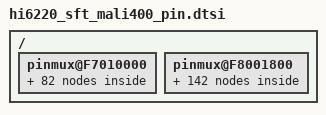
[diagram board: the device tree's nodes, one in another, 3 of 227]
/ {
    pinmux@F7010000 {
		gpio037_pmx_func: gpio037_pmx_func {
                     pinctrl-single,pins = <0x0    0x0>;
		};
		gpio037_pmx_idle: gpio037_pmx_idle {
                     pinctrl-single,pins = <0x0    0x0>;
		};

		gpio040_pmx_func: gpio040_pmx_func {
                     pinctrl-single,pins = <0x4    0x0>;
		};
		gpio040_pmx_idle: gpio040_pmx_idle {
                     pinctrl-single,pins = <0x4    0x0>;
		};

		gpio041_pmx_func: gpio041_pmx_func {
                     pinctrl-single,pins = <0x8    0x0>;
		};
		gpio041_pmx_idle: gpio041_pmx_idle {
                     pinctrl-single,pins = <0x8    0x0>;
		};

		gpio044_pmx_func: gpio044_pmx_func {
                     pinctrl-single,pins = <0xC    0x0>;
		};
		gpio044_pmx_idle: gpio044_pmx_idle {
                     pinctrl-single,pins = <0xC    0x0>;
		};

		gpio045_pmx_func: gpio045_pmx_func {
                     pinctrl-single,pins = <0x10    0x0>;
		};
		gpio045_pmx_idle: gpio045_pmx_idle {
                     pinctrl-single,pins = <0x10    0x0>;
		};

		gpio046_pmx_func: gpio046_pmx_func {
                     pinctrl-single,pins = <0x14    0x0>;
		};
		gpio046_pmx_idle: gpio046_pmx_idle {
                     pinctrl-single,pins = <0x14    0x0>;
		};

		gpio047_pmx_func: gpio047_pmx_func {
                     pinctrl-single,pins = <0x18    0x0>;
		};
		gpio047_pmx_idle: gpio047_pmx_idle {
                     pinctrl-single,pins = <0x18    0x0>;
		};

		gpio048_pmx_func: gpio048_pmx_func {
                     pinctrl-single,pins = <0x1C    0x0>;
		};
		gpio048_pmx_idle: gpio048_pmx_idle {
                     pinctrl-single,pins = <0x1C    0x0>;
		};

		gpio049_pmx_func: gpio049_pmx_func {
                     pinctrl-single,pins = <0x20    0x0>;
		};
		gpio049_pmx_idle: gpio049_pmx_idle {
                     pinctrl-single,pins = <0x20    0x0>;
		};

		gpio051_pmx_func: gpio051_pmx_func {
                     pinctrl-single,pins = <0x24    0x0>;
		};
		gpio051_pmx_idle: gpio051_pmx_idle {
                     pinctrl-single,pins = <0x24    0x0>;
		};

		gpio052_pmx_func: gpio052_pmx_func {
                     pinctrl-single,pins = <0x28    0x0>;
		};
		gpio052_pmx_idle: gpio052_pmx_idle {
                     pinctrl-single,pins = <0x28    0x0>;
		};

		gpio053_pmx_func: gpio053_pmx_func {
                     pinctrl-single,pins = <0x2C    0x0>;
		};
		gpio053_pmx_idle: gpio053_pmx_idle {
                     pinctrl-single,pins = <0x2C    0x0>;
		};

		gpio054_pmx_func: gpio054_pmx_func {
                     pinctrl-single,pins = <0x30    0x0>;
		};
		gpio054_pmx_idle: gpio054_pmx_idle {
                     pinctrl-single,pins = <0x30    0x0>;
		};

		gpio056_pmx_func: gpio056_pmx_func {
                     pinctrl-single,pins = <0x34    0x0>;
		};
		gpio056_pmx_idle: gpio056_pmx_idle {
                     pinctrl-single,pins = <0x34    0x0>;
		};

		gpio057_pmx_func: gpio057_pmx_func {
                     pinctrl-single,pins = <0x38    0x0>;
		};
		gpio057_pmx_idle: gpio057_pmx_idle {
                     pinctrl-single,pins = <0x38    0x0>;
		};

		gpio058_pmx_func: gpio058_pmx_func {
                     pinctrl-single,pins = <0x3C    0x0>;
		};
		gpio058_pmx_idle: gpio058_pmx_idle {
                     pinctrl-single,pins = <0x3C    0x0>;
		};

		gpio059_pmx_func: gpio059_pmx_func {
                     pinctrl-single,pins = <0x40    0x0>;
		};
		gpio059_pmx_idle: gpio059_pmx_idle {
                     pinctrl-single,pins = <0x40    0x0>;
		};

		gpio062_pmx_func: gpio062_pmx_func {
                     pinctrl-single,pins = <0x44    0x0>;
		};
		gpio062_pmx_idle: gpio062_pmx_idle {
                     pinctrl-single,pins = <0x44    0x0>;
		};

		gpio063_pmx_func: gpio063_pmx_func {
                     pinctrl-single,pins = <0x48    0x0>;
		};
		gpio063_pmx_idle: gpio063_pmx_idle {
                     pinctrl-single,pins = <0x48    0x0>;
		};

		gpio064_pmx_func: gpio064_pmx_func {
                     pinctrl-single,pins = <0x4C    0x0>;
		};
		gpio064_pmx_idle: gpio064_pmx_idle {
                     pinctrl-single,pins = <0x4C    0x0>;
		};

		gpio065_pmx_func: gpio065_pmx_func {
                     pinctrl-single,pins = <0x50    0x0>;
		};
		gpio065_pmx_idle: gpio065_pmx_idle {
                     pinctrl-single,pins = <0x50    0x0>;
		};

		gpio066_pmx_func: gpio066_pmx_func {
                     pinctrl-single,pins = <0x54    0x0>;
		};
		gpio066_pmx_idle: gpio066_pmx_idle {
                     pinctrl-single,pins = <0x54    0x0>;
		};

		gpio067_pmx_func: gpio067_pmx_func {
                     pinctrl-single,pins = <0x58    0x0>;
		};
		gpio067_pmx_idle: gpio067_pmx_idle {
                     pinctrl-single,pins = <0x58    0x0>;
		};

		gpio068_pmx_func: gpio068_pmx_func {
                     pinctrl-single,pins = <0x5C    0x0>;
		};
		gpio068_pmx_idle: gpio068_pmx_idle {
                     pinctrl-single,pins = <0x5C    0x0>;
		};

		gpio071_pmx_func: gpio071_pmx_func {
                     pinctrl-single,pins = <0x60    0x0>;
		};
		gpio071_pmx_idle: gpio071_pmx_idle {
                     pinctrl-single,pins = <0x60    0x0>;
		};

		gpio072_pmx_func: gpio072_pmx_func {
                     pinctrl-single,pins = <0x64    0x0>;
		};
		gpio072_pmx_idle: gpio072_pmx_idle {
                     pinctrl-single,pins = <0x64    0x0>;
		};

		gpio074_pmx_func: gpio074_pmx_func {
                     pinctrl-single,pins = <0x68    0x0>;
		};
		gpio074_pmx_idle: gpio074_pmx_idle {
                     pinctrl-single,pins = <0x68    0x0>;
		};

		gpio075_pmx_func: gpio075_pmx_func {
                     pinctrl-single,pins = <0x6C    0x0>;
		};
		gpio075_pmx_idle: gpio075_pmx_idle {
                     pinctrl-single,pins = <0x6C    0x0>;
		};

		gpio077_pmx_func: gpio077_pmx_func {
                     pinctrl-single,pins = <0x70    0x0>;
		};
		gpio077_pmx_idle: gpio077_pmx_idle {
                     pinctrl-single,pins = <0x70    0x0>;
		};

		gpio078_pmx_func: gpio078_pmx_func {
                     pinctrl-single,pins = <0x74    0x0>;
		};
		gpio078_pmx_idle: gpio078_pmx_idle {
                     pinctrl-single,pins = <0x74    0x0>;
		};

		gpio079_pmx_func: gpio079_pmx_func {
                     pinctrl-single,pins = <0x78    0x0>;
		};
		gpio079_pmx_idle: gpio079_pmx_idle {
                     pinctrl-single,pins = <0x78    0x0>;
		};

		gpio080_pmx_func: gpio080_pmx_func {
                     pinctrl-single,pins = <0x7C    0x0>;
		};
		gpio080_pmx_idle: gpio080_pmx_idle {
                     pinctrl-single,pins = <0x7C    0x0>;
		};

		gpio081_pmx_func: gpio081_pmx_func {
                     pinctrl-single,pins = <0x80    0x0>;
		};
		gpio081_pmx_idle: gpio081_pmx_idle {
                     pinctrl-single,pins = <0x80    0x0>;
		};

		gpio082_pmx_func: gpio082_pmx_func {
                     pinctrl-single,pins = <0x84    0x0>;
		};
		gpio082_pmx_idle: gpio082_pmx_idle {
                     pinctrl-single,pins = <0x84    0x0>;
		};

		gpio084_pmx_func: gpio084_pmx_func {
                     pinctrl-single,pins = <0x88    0x0>;
		};
		gpio084_pmx_idle: gpio084_pmx_idle {
                     pinctrl-single,pins = <0x88    0x0>;
		};

		gpio085_pmx_func: gpio085_pmx_func {
                     pinctrl-single,pins = <0x8C    0x0>;
		};
		gpio085_pmx_idle: gpio085_pmx_idle {
                     pinctrl-single,pins = <0x8C    0x0>;
		};

		gpio086_pmx_func: gpio086_pmx_func {
                     pinctrl-single,pins = <0x90    0x0>;
		};
		gpio086_pmx_idle: gpio086_pmx_idle {
                     pinctrl-single,pins = <0x90    0x0>;
		};

		gpio087_pmx_func: gpio087_pmx_func {
                     pinctrl-single,pins = <0x94    0x0>;
		};
		gpio087_pmx_idle: gpio087_pmx_idle {
                     pinctrl-single,pins = <0x94    0x0>;
		};

		gpio088_pmx_func: gpio088_pmx_func {
                     pinctrl-single,pins = <0x98    0x0>;
		};
		gpio088_pmx_idle: gpio088_pmx_idle {
                     pinctrl-single,pins = <0x98    0x0>;
		};

		gpio089_pmx_func: gpio089_pmx_func {
                     pinctrl-single,pins = <0x9C    0x0>;
		};
		gpio089_pmx_idle: gpio089_pmx_idle {
                     pinctrl-single,pins = <0x9C    0x0>;
		};

		gpio090_pmx_func: gpio090_pmx_func {
                     pinctrl-single,pins = <0xA0    0x0>;
		};
		gpio090_pmx_idle: gpio090_pmx_idle {
                     pinctrl-single,pins = <0xA0    0x0>;
		};

    };

    pinmux@F8001800 {
		gpio000_cfg_func: gpio000_cfg_func {
                     pinctrl-single,pins = <0x10  0>;
                     pinctrl-single,bias-pulldown = <0 2 0 2>;
                     pinctrl-single,bias-pullup = <0 1 0 1>;
                     pinctrl-single,drive-strength = <0x20 0x70>;
                     pinctrl-single,slew-rate = <0x0 0x80>;
		};
		gpio000_cfg_idle: gpio000_cfg_idle {
                     pinctrl-single,pins = <0x10  0>;
                     pinctrl-single,bias-pulldown = <0 2 0 2>;
                     pinctrl-single,bias-pullup = <0 1 0 1>;
                     pinctrl-single,drive-strength = <0x20 0x70>;
                     pinctrl-single,slew-rate = <0x0 0x80>;
		};

		gpio004_cfg_func: gpio004_cfg_func {
                     pinctrl-single,pins = <0x14  0>;
                     pinctrl-single,bias-pulldown = <0 2 0 2>;
                     pinctrl-single,bias-pullup = <0 1 0 1>;
                     pinctrl-single,drive-strength = <0x20 0x70>;
                     pinctrl-single,slew-rate = <0x0 0x80>;
		};
		gpio004_cfg_idle: gpio004_cfg_idle {
                     pinctrl-single,pins = <0x14  0>;
                     pinctrl-single,bias-pulldown = <0 2 0 2>;
                     pinctrl-single,bias-pullup = <0 1 0 1>;
                     pinctrl-single,drive-strength = <0x20 0x70>;
                     pinctrl-single,slew-rate = <0x0 0x80>;
		};

		gpio006_cfg_func: gpio006_cfg_func {
                     pinctrl-single,pins = <0x18  0>;
                     pinctrl-single,bias-pulldown = <0 2 0 2>;
                     pinctrl-single,bias-pullup = <0 1 0 1>;
                     pinctrl-single,drive-strength = <0x20 0x70>;
                     pinctrl-single,slew-rate = <0x0 0x80>;
		};
		gpio006_cfg_idle: gpio006_cfg_idle {
                     pinctrl-single,pins = <0x18  0>;
                     pinctrl-single,bias-pulldown = <0 2 0 2>;
                     pinctrl-single,bias-pullup = <0 1 0 1>;
                     pinctrl-single,drive-strength = <0x20 0x70>;
                     pinctrl-single,slew-rate = <0x0 0x80>;
		};

		gpio007_cfg_func: gpio007_cfg_func {
                     pinctrl-single,pins = <0x1C  0>;
                     pinctrl-single,bias-pulldown = <0 2 0 2>;
                     pinctrl-single,bias-pullup = <0 1 0 1>;
                     pinctrl-single,drive-strength = <0x20 0x70>;
                     pinctrl-single,slew-rate = <0x0 0x80>;
		};
		gpio007_cfg_idle: gpio007_cfg_idle {
                     pinctrl-single,pins = <0x1C  0>;
                     pinctrl-single,bias-pulldown = <0 2 0 2>;
                     pinctrl-single,bias-pullup = <0 1 0 1>;
                     pinctrl-single,drive-strength = <0x20 0x70>;
                     pinctrl-single,slew-rate = <0x0 0x80>;
		};

		gpio010_cfg_func: gpio010_cfg_func {
                     pinctrl-single,pins = <0x20  0>;
                     pinctrl-single,bias-pulldown = <0 2 0 2>;
                     pinctrl-single,bias-pullup = <0 1 0 1>;
                     pinctrl-single,drive-strength = <0x20 0x70>;
                     pinctrl-single,slew-rate = <0x0 0x80>;
		};
		gpio010_cfg_idle: gpio010_cfg_idle {
                     pinctrl-single,pins = <0x20  0>;
                     pinctrl-single,bias-pulldown = <0 2 0 2>;
                     pinctrl-single,bias-pullup = <0 1 0 1>;
                     pinctrl-single,drive-strength = <0x20 0x70>;
                     pinctrl-single,slew-rate = <0x0 0x80>;
		};

		gpio011_cfg_func: gpio011_cfg_func {
                     pinctrl-single,pins = <0x24  0>;
                     pinctrl-single,bias-pulldown = <0 2 0 2>;
                     pinctrl-single,bias-pullup = <0 1 0 1>;
                     pinctrl-single,drive-strength = <0x20 0x70>;
                     pinctrl-single,slew-rate = <0x0 0x80>;
		};
		gpio011_cfg_idle: gpio011_cfg_idle {
                     pinctrl-single,pins = <0x24  0>;
                     pinctrl-single,bias-pulldown = <0 2 0 2>;
                     pinctrl-single,bias-pullup = <0 1 0 1>;
                     pinctrl-single,drive-strength = <0x20 0x70>;
                     pinctrl-single,slew-rate = <0x0 0x80>;
		};

		gpio012_cfg_func: gpio012_cfg_func {
                     pinctrl-single,pins = <0x28  0>;
                     pinctrl-single,bias-pulldown = <0 2 0 2>;
                     pinctrl-single,bias-pullup = <0 1 0 1>;
                     pinctrl-single,drive-strength = <0x20 0x70>;
                     pinctrl-single,slew-rate = <0x0 0x80>;
		};
		gpio012_cfg_idle: gpio012_cfg_idle {
                     pinctrl-single,pins = <0x28  0>;
                     pinctrl-single,bias-pulldown = <0 2 0 2>;
                     pinctrl-single,bias-pullup = <0 1 0 1>;
                     pinctrl-single,drive-strength = <0x20 0x70>;
                     pinctrl-single,slew-rate = <0x0 0x80>;
		};

		gpio016_cfg_func: gpio016_cfg_func {
                     pinctrl-single,pins = <0x2C  0>;
                     pinctrl-single,bias-pulldown = <0 2 0 2>;
                     pinctrl-single,bias-pullup = <0 1 0 1>;
                     pinctrl-single,drive-strength = <0x20 0x70>;
                     pinctrl-single,slew-rate = <0x0 0x80>;
		};
		gpio016_cfg_idle: gpio016_cfg_idle {
                     pinctrl-single,pins = <0x2C  0>;
                     pinctrl-single,bias-pulldown = <0 2 0 2>;
                     pinctrl-single,bias-pullup = <0 1 0 1>;
                     pinctrl-single,drive-strength = <0x20 0x70>;
                     pinctrl-single,slew-rate = <0x0 0x80>;
		};

		gpio017_cfg_func: gpio017_cfg_func {
                     pinctrl-single,pins = <0x30  0>;
                     pinctrl-single,bias-pulldown = <0 2 0 2>;
                     pinctrl-single,bias-pullup = <0 1 0 1>;
                     pinctrl-single,drive-strength = <0x20 0x70>;
                     pinctrl-single,slew-rate = <0x0 0x80>;
		};
		gpio017_cfg_idle: gpio017_cfg_idle {
                     pinctrl-single,pins = <0x30  0>;
                     pinctrl-single,bias-pulldown = <0 2 0 2>;
                     pinctrl-single,bias-pullup = <0 1 0 1>;
                     pinctrl-single,drive-strength = <0x20 0x70>;
                     pinctrl-single,slew-rate = <0x0 0x80>;
		};

		gpio019_cfg_func: gpio019_cfg_func {
                     pinctrl-single,pins = <0x34  0>;
                     pinctrl-single,bias-pulldown = <0 2 0 2>;
                     pinctrl-single,bias-pullup = <0 1 0 1>;
                     pinctrl-single,drive-strength = <0x20 0x70>;
                     pinctrl-single,slew-rate = <0x0 0x80>;
		};
		gpio019_cfg_idle: gpio019_cfg_idle {
                     pinctrl-single,pins = <0x34  0>;
                     pinctrl-single,bias-pulldown = <0 2 0 2>;
                     pinctrl-single,bias-pullup = <0 1 0 1>;
                     pinctrl-single,drive-strength = <0x20 0x70>;
                     pinctrl-single,slew-rate = <0x0 0x80>;
		};

		gpio020_cfg_func: gpio020_cfg_func {
                     pinctrl-single,pins = <0x38  0>;
                     pinctrl-single,bias-pulldown = <0 2 0 2>;
                     pinctrl-single,bias-pullup = <0 1 0 1>;
                     pinctrl-single,drive-strength = <0x20 0x70>;
                     pinctrl-single,slew-rate = <0x0 0x80>;
		};
		gpio020_cfg_idle: gpio020_cfg_idle {
                     pinctrl-single,pins = <0x38  0>;
                     pinctrl-single,bias-pulldown = <0 2 0 2>;
                     pinctrl-single,bias-pullup = <0 1 0 1>;
                     pinctrl-single,drive-strength = <0x20 0x70>;
                     pinctrl-single,slew-rate = <0x0 0x80>;
		};

		gpio021_cfg_func: gpio021_cfg_func {
                     pinctrl-single,pins = <0x3C  0>;
                     pinctrl-single,bias-pulldown = <0 2 0 2>;
                     pinctrl-single,bias-pullup = <0 1 0 1>;
                     pinctrl-single,drive-strength = <0x20 0x70>;
                     pinctrl-single,slew-rate = <0x0 0x80>;
		};
		gpio021_cfg_idle: gpio021_cfg_idle {
                     pinctrl-single,pins = <0x3C  0>;
                     pinctrl-single,bias-pulldown = <0 2 0 2>;
                     pinctrl-single,bias-pullup = <0 1 0 1>;
                     pinctrl-single,drive-strength = <0x20 0x70>;
                     pinctrl-single,slew-rate = <0x0 0x80>;
		};

		gpio022_cfg_func: gpio022_cfg_func {
                     pinctrl-single,pins = <0x40  0>;
                     pinctrl-single,bias-pulldown = <0 2 0 2>;
                     pinctrl-single,bias-pullup = <0 1 0 1>;
                     pinctrl-single,drive-strength = <0x20 0x70>;
                     pinctrl-single,slew-rate = <0x0 0x80>;
		};
		gpio022_cfg_idle: gpio022_cfg_idle {
                     pinctrl-single,pins = <0x40  0>;
                     pinctrl-single,bias-pulldown = <0 2 0 2>;
                     pinctrl-single,bias-pullup = <0 1 0 1>;
                     pinctrl-single,drive-strength = <0x20 0x70>;
                     pinctrl-single,slew-rate = <0x0 0x80>;
		};

		gpio023_cfg_func: gpio023_cfg_func {
                     pinctrl-single,pins = <0x44  0>;
                     pinctrl-single,bias-pulldown = <0 2 0 2>;
                     pinctrl-single,bias-pullup = <0 1 0 1>;
                     pinctrl-single,drive-strength = <0x20 0x70>;
                     pinctrl-single,slew-rate = <0x0 0x80>;
		};
		gpio023_cfg_idle: gpio023_cfg_idle {
                     pinctrl-single,pins = <0x44  0>;
                     pinctrl-single,bias-pulldown = <0 2 0 2>;
                     pinctrl-single,bias-pullup = <0 1 0 1>;
                     pinctrl-single,drive-strength = <0x20 0x70>;
                     pinctrl-single,slew-rate = <0x0 0x80>;
		};

		gpio024_cfg_func: gpio024_cfg_func {
                     pinctrl-single,pins = <0x48  0>;
                     pinctrl-single,bias-pulldown = <0 2 0 2>;
                     pinctrl-single,bias-pullup = <0 1 0 1>;
                     pinctrl-single,drive-strength = <0x20 0x70>;
                     pinctrl-single,slew-rate = <0x0 0x80>;
		};
		gpio024_cfg_idle: gpio024_cfg_idle {
                     pinctrl-single,pins = <0x48  0>;
                     pinctrl-single,bias-pulldown = <0 2 0 2>;
                     pinctrl-single,bias-pullup = <0 1 0 1>;
                     pinctrl-single,drive-strength = <0x20 0x70>;
                     pinctrl-single,slew-rate = <0x0 0x80>;
		};

		gpio025_cfg_func: gpio025_cfg_func {
                     pinctrl-single,pins = <0x4C  0>;
                     pinctrl-single,bias-pulldown = <0 2 0 2>;
                     pinctrl-single,bias-pullup = <0 1 0 1>;
                     pinctrl-single,drive-strength = <0x20 0x70>;
                     pinctrl-single,slew-rate = <0x0 0x80>;
		};
		gpio025_cfg_idle: gpio025_cfg_idle {
                     pinctrl-single,pins = <0x4C  0>;
                     pinctrl-single,bias-pulldown = <0 2 0 2>;
                     pinctrl-single,bias-pullup = <0 1 0 1>;
                     pinctrl-single,drive-strength = <0x20 0x70>;
                     pinctrl-single,slew-rate = <0x0 0x80>;
		};

		gpio026_cfg_func: gpio026_cfg_func {
                     pinctrl-single,pins = <0x50  0>;
                     pinctrl-single,bias-pulldown = <0 2 0 2>;
                     pinctrl-single,bias-pullup = <0 1 0 1>;
                     pinctrl-single,drive-strength = <0x20 0x70>;
                     pinctrl-single,slew-rate = <0x0 0x80>;
		};
		gpio026_cfg_idle: gpio026_cfg_idle {
                     pinctrl-single,pins = <0x50  0>;
                     pinctrl-single,bias-pulldown = <0 2 0 2>;
                     pinctrl-single,bias-pullup = <0 1 0 1>;
                     pinctrl-single,drive-strength = <0x20 0x70>;
                     pinctrl-single,slew-rate = <0x0 0x80>;
		};

		gpio027_cfg_func: gpio027_cfg_func {
                     pinctrl-single,pins = <0x54  0>;
                     pinctrl-single,bias-pulldown = <0 2 0 2>;
                     pinctrl-single,bias-pullup = <0 1 0 1>;
                     pinctrl-single,drive-strength = <0x20 0x70>;
                     pinctrl-single,slew-rate = <0x0 0x80>;
		};
		gpio027_cfg_idle: gpio027_cfg_idle {
                     pinctrl-single,pins = <0x54  0>;
                     pinctrl-single,bias-pulldown = <0 2 0 2>;
                     pinctrl-single,bias-pullup = <0 1 0 1>;
                     pinctrl-single,drive-strength = <0x20 0x70>;
                     pinctrl-single,slew-rate = <0x0 0x80>;
		};

		gpio028_cfg_func: gpio028_cfg_func {
                     pinctrl-single,pins = <0x58  0>;
                     pinctrl-single,bias-pulldown = <0 2 0 2>;
                     pinctrl-single,bias-pullup = <0 1 0 1>;
                     pinctrl-single,drive-strength = <0x20 0x70>;
                     pinctrl-single,slew-rate = <0x0 0x80>;
		};
		gpio028_cfg_idle: gpio028_cfg_idle {
                     pinctrl-single,pins = <0x58  0>;
                     pinctrl-single,bias-pulldown = <0 2 0 2>;
                     pinctrl-single,bias-pullup = <0 1 0 1>;
                     pinctrl-single,drive-strength = <0x20 0x70>;
                     pinctrl-single,slew-rate = <0x0 0x80>;
		};

		gpio029_cfg_func: gpio029_cfg_func {
                     pinctrl-single,pins = <0x5C  0>;
                     pinctrl-single,bias-pulldown = <0 2 0 2>;
                     pinctrl-single,bias-pullup = <0 1 0 1>;
                     pinctrl-single,drive-strength = <0x20 0x70>;
                     pinctrl-single,slew-rate = <0x0 0x80>;
		};
		gpio029_cfg_idle: gpio029_cfg_idle {
                     pinctrl-single,pins = <0x5C  0>;
                     pinctrl-single,bias-pulldown = <0 2 0 2>;
                     pinctrl-single,bias-pullup = <0 1 0 1>;
                     pinctrl-single,drive-strength = <0x20 0x70>;
                     pinctrl-single,slew-rate = <0x0 0x80>;
		};

		gpio030_cfg_func: gpio030_cfg_func {
                     pinctrl-single,pins = <0x60  0>;
                     pinctrl-single,bias-pulldown = <0 2 0 2>;
                     pinctrl-single,bias-pullup = <0 1 0 1>;
                     pinctrl-single,drive-strength = <0x20 0x70>;
                     pinctrl-single,slew-rate = <0x0 0x80>;
		};
		gpio030_cfg_idle: gpio030_cfg_idle {
                     pinctrl-single,pins = <0x60  0>;
                     pinctrl-single,bias-pulldown = <0 2 0 2>;
                     pinctrl-single,bias-pullup = <0 1 0 1>;
                     pinctrl-single,drive-strength = <0x20 0x70>;
                     pinctrl-single,slew-rate = <0x0 0x80>;
		};

		gpio031_cfg_func: gpio031_cfg_func {
                     pinctrl-single,pins = <0x64  0>;
                     pinctrl-single,bias-pulldown = <0 2 0 2>;
                     pinctrl-single,bias-pullup = <0 1 0 1>;
                     pinctrl-single,drive-strength = <0x20 0x70>;
                     pinctrl-single,slew-rate = <0x0 0x80>;
		};
		gpio031_cfg_idle: gpio031_cfg_idle {
                     pinctrl-single,pins = <0x64  0>;
                     pinctrl-single,bias-pulldown = <0 2 0 2>;
                     pinctrl-single,bias-pullup = <0 1 0 1>;
                     pinctrl-single,drive-strength = <0x20 0x70>;
                     pinctrl-single,slew-rate = <0x0 0x80>;
		};

		gpio032_cfg_func: gpio032_cfg_func {
                     pinctrl-single,pins = <0x68  0>;
                     pinctrl-single,bias-pulldown = <0 2 0 2>;
                     pinctrl-single,bias-pullup = <0 1 0 1>;
                     pinctrl-single,drive-strength = <0x20 0x70>;
                     pinctrl-single,slew-rate = <0x0 0x80>;
		};
		gpio032_cfg_idle: gpio032_cfg_idle {
                     pinctrl-single,pins = <0x68  0>;
                     pinctrl-single,bias-pulldown = <0 2 0 2>;
                     pinctrl-single,bias-pullup = <0 1 0 1>;
                     pinctrl-single,drive-strength = <0x20 0x70>;
                     pinctrl-single,slew-rate = <0x0 0x80>;
		};

		gpio033_cfg_func: gpio033_cfg_func {
                     pinctrl-single,pins = <0x6C  0>;
                     pinctrl-single,bias-pulldown = <0 2 0 2>;
                     pinctrl-single,bias-pullup = <0 1 0 1>;
                     pinctrl-single,drive-strength = <0x20 0x70>;
                     pinctrl-single,slew-rate = <0x0 0x80>;
		};
		gpio033_cfg_idle: gpio033_cfg_idle {
                     pinctrl-single,pins = <0x6C  0>;
                     pinctrl-single,bias-pulldown = <0 2 0 2>;
                     pinctrl-single,bias-pullup = <0 1 0 1>;
                     pinctrl-single,drive-strength = <0x20 0x70>;
                     pinctrl-single,slew-rate = <0x0 0x80>;
		};

		gpio034_cfg_func: gpio034_cfg_func {
                     pinctrl-single,pins = <0x70  0>;
                     pinctrl-single,bias-pulldown = <0 2 0 2>;
                     pinctrl-single,bias-pullup = <0 1 0 1>;
                     pinctrl-single,drive-strength = <0x20 0x70>;
                     pinctrl-single,slew-rate = <0x0 0x80>;
		};
		gpio034_cfg_idle: gpio034_cfg_idle {
                     pinctrl-single,pins = <0x70  0>;
                     pinctrl-single,bias-pulldown = <0 2 0 2>;
                     pinctrl-single,bias-pullup = <0 1 0 1>;
                     pinctrl-single,drive-strength = <0x20 0x70>;
                     pinctrl-single,slew-rate = <0x0 0x80>;
		};

		gpio035_cfg_func: gpio035_cfg_func {
                     pinctrl-single,pins = <0x74  0>;
                     pinctrl-single,bias-pulldown = <0 2 0 2>;
                     pinctrl-single,bias-pullup = <0 1 0 1>;
                     pinctrl-single,drive-strength = <0x20 0x70>;
                     pinctrl-single,slew-rate = <0x0 0x80>;
		};
		gpio035_cfg_idle: gpio035_cfg_idle {
                     pinctrl-single,pins = <0x74  0>;
                     pinctrl-single,bias-pulldown = <0 2 0 2>;
                     pinctrl-single,bias-pullup = <0 1 0 1>;
                     pinctrl-single,drive-strength = <0x20 0x70>;
                     pinctrl-single,slew-rate = <0x0 0x80>;
		};

		gpio036_cfg_func: gpio036_cfg_func {
                     pinctrl-single,pins = <0xA8  0>;
                     pinctrl-single,bias-pulldown = <0 2 0 2>;
                     pinctrl-single,bias-pullup = <0 1 0 1>;
                     pinctrl-single,drive-strength = <0x20 0x70>;
                     pinctrl-single,slew-rate = <0x0 0x80>;
		};
		gpio036_cfg_idle: gpio036_cfg_idle {
                     pinctrl-single,pins = <0xA8  0>;
                     pinctrl-single,bias-pulldown = <0 2 0 2>;
                     pinctrl-single,bias-pullup = <0 1 0 1>;
                     pinctrl-single,drive-strength = <0x20 0x70>;
                     pinctrl-single,slew-rate = <0x0 0x80>;
		};

		gpio037_cfg_func: gpio037_cfg_func {
                     pinctrl-single,pins = <0x0  0>;
                     pinctrl-single,bias-pulldown = <0 2 0 2>;
                     pinctrl-single,bias-pullup = <0 1 0 1>;
                     pinctrl-single,drive-strength = <0x20 0x70>;
                     pinctrl-single,slew-rate = <0x0 0x80>;
		};
		gpio037_cfg_idle: gpio037_cfg_idle {
                     pinctrl-single,pins = <0x0  0>;
                     pinctrl-single,bias-pulldown = <0 2 0 2>;
                     pinctrl-single,bias-pullup = <0 1 0 1>;
                     pinctrl-single,drive-strength = <0x20 0x70>;
                     pinctrl-single,slew-rate = <0x0 0x80>;
		};

		gpio038_cfg_func: gpio038_cfg_func {
                     pinctrl-single,pins = <0xAC  0>;
                     pinctrl-single,bias-pulldown = <0 2 0 2>;
                     pinctrl-single,bias-pullup = <0 1 0 1>;
                     pinctrl-single,drive-strength = <0x20 0x70>;
                     pinctrl-single,slew-rate = <0x0 0x80>;
		};
		gpio038_cfg_idle: gpio038_cfg_idle {
                     pinctrl-single,pins = <0xAC  0>;
                     pinctrl-single,bias-pulldown = <0 2 0 2>;
                     pinctrl-single,bias-pullup = <0 1 0 1>;
                     pinctrl-single,drive-strength = <0x20 0x70>;
                     pinctrl-single,slew-rate = <0x0 0x80>;
		};

		gpio039_cfg_func: gpio039_cfg_func {
                     pinctrl-single,pins = <0xB0  0>;
                     pinctrl-single,bias-pulldown = <0 2 0 2>;
                     pinctrl-single,bias-pullup = <0 1 0 1>;
                     pinctrl-single,drive-strength = <0x20 0x70>;
                     pinctrl-single,slew-rate = <0x0 0x80>;
		};
		gpio039_cfg_idle: gpio039_cfg_idle {
                     pinctrl-single,pins = <0xB0  0>;
                     pinctrl-single,bias-pulldown = <0 2 0 2>;
                     pinctrl-single,bias-pullup = <0 1 0 1>;
                     pinctrl-single,drive-strength = <0x20 0x70>;
                     pinctrl-single,slew-rate = <0x0 0x80>;
		};

		gpio040_cfg_func: gpio040_cfg_func {
                     pinctrl-single,pins = <0x4  0>;
                     pinctrl-single,bias-pulldown = <0 2 0 2>;
                     pinctrl-single,bias-pullup = <0 1 0 1>;
                     pinctrl-single,drive-strength = <0x20 0x70>;
                     pinctrl-single,slew-rate = <0x0 0x80>;
		};
		gpio040_cfg_idle: gpio040_cfg_idle {
                     pinctrl-single,pins = <0x4  0>;
                     pinctrl-single,bias-pulldown = <0 2 0 2>;
                     pinctrl-single,bias-pullup = <0 1 0 1>;
                     pinctrl-single,drive-strength = <0x20 0x70>;
                     pinctrl-single,slew-rate = <0x0 0x80>;
		};

		gpio041_cfg_func: gpio041_cfg_func {
                     pinctrl-single,pins = <0x8  0>;
                     pinctrl-single,bias-pulldown = <0 2 0 2>;
                     pinctrl-single,bias-pullup = <0 1 0 1>;
                     pinctrl-single,drive-strength = <0x20 0x70>;
                     pinctrl-single,slew-rate = <0x0 0x80>;
		};
		gpio041_cfg_idle: gpio041_cfg_idle {
                     pinctrl-single,pins = <0x8  0>;
                     pinctrl-single,bias-pulldown = <0 2 0 2>;
                     pinctrl-single,bias-pullup = <0 1 0 1>;
                     pinctrl-single,drive-strength = <0x20 0x70>;
                     pinctrl-single,slew-rate = <0x0 0x80>;
		};

		gpio044_cfg_func: gpio044_cfg_func {
                     pinctrl-single,pins = <0xC  0>;
                     pinctrl-single,bias-pulldown = <0 2 0 2>;
                     pinctrl-single,bias-pullup = <0 1 0 1>;
                     pinctrl-single,drive-strength = <0x10 0x70>;
                     pinctrl-single,slew-rate = <0x0 0x80>;
		};
		gpio044_cfg_idle: gpio044_cfg_idle {
                     pinctrl-single,pins = <0xC  0>;
                     pinctrl-single,bias-pulldown = <0 2 0 2>;
                     pinctrl-single,bias-pullup = <0 1 0 1>;
                     pinctrl-single,drive-strength = <0x10 0x70>;
                     pinctrl-single,slew-rate = <0x0 0x80>;
		};

		gpio045_cfg_func: gpio045_cfg_func {
                     pinctrl-single,pins = <0x10  0>;
                     pinctrl-single,bias-pulldown = <0 2 0 2>;
                     pinctrl-single,bias-pullup = <0 1 0 1>;
                     pinctrl-single,drive-strength = <0x10 0x70>;
                     pinctrl-single,slew-rate = <0x0 0x80>;
		};
		gpio045_cfg_idle: gpio045_cfg_idle {
                     pinctrl-single,pins = <0x10  0>;
                     pinctrl-single,bias-pulldown = <0 2 0 2>;
                     pinctrl-single,bias-pullup = <0 1 0 1>;
                     pinctrl-single,drive-strength = <0x10 0x70>;
                     pinctrl-single,slew-rate = <0x0 0x80>;
		};

		gpio046_cfg_func: gpio046_cfg_func {
                     pinctrl-single,pins = <0x14  0>;
                     pinctrl-single,bias-pulldown = <0 2 0 2>;
                     pinctrl-single,bias-pullup = <0 1 0 1>;
                     pinctrl-single,drive-strength = <0x10 0x70>;
                     pinctrl-single,slew-rate = <0x0 0x80>;
		};
		gpio046_cfg_idle: gpio046_cfg_idle {
                     pinctrl-single,pins = <0x14  0>;
                     pinctrl-single,bias-pulldown = <0 2 0 2>;
                     pinctrl-single,bias-pullup = <0 1 0 1>;
                     pinctrl-single,drive-strength = <0x10 0x70>;
                     pinctrl-single,slew-rate = <0x0 0x80>;
		};

		gpio047_cfg_func: gpio047_cfg_func {
                     pinctrl-single,pins = <0x18  0>;
                     pinctrl-single,bias-pulldown = <0 2 0 2>;
                     pinctrl-single,bias-pullup = <0 1 0 1>;
                     pinctrl-single,drive-strength = <0x10 0x70>;
                     pinctrl-single,slew-rate = <0x0 0x80>;
		};
		gpio047_cfg_idle: gpio047_cfg_idle {
                     pinctrl-single,pins = <0x18  0>;
                     pinctrl-single,bias-pulldown = <0 2 0 2>;
                     pinctrl-single,bias-pullup = <0 1 0 1>;
                     pinctrl-single,drive-strength = <0x10 0x70>;
                     pinctrl-single,slew-rate = <0x0 0x80>;
		};

		gpio048_cfg_func: gpio048_cfg_func {
                     pinctrl-single,pins = <0x1C  0>;
                     pinctrl-single,bias-pulldown = <0 2 0 2>;
                     pinctrl-single,bias-pullup = <0 1 0 1>;
                     pinctrl-single,drive-strength = <0x10 0x70>;
                     pinctrl-single,slew-rate = <0x0 0x80>;
		};
		gpio048_cfg_idle: gpio048_cfg_idle {
                     pinctrl-single,pins = <0x1C  0>;
                     pinctrl-single,bias-pulldown = <0 2 0 2>;
                     pinctrl-single,bias-pullup = <0 1 0 1>;
                     pinctrl-single,drive-strength = <0x10 0x70>;
                     pinctrl-single,slew-rate = <0x0 0x80>;
		};

		gpio049_cfg_func: gpio049_cfg_func {
                     pinctrl-single,pins = <0x20  0>;
                     pinctrl-single,bias-pulldown = <0 2 0 2>;
                     pinctrl-single,bias-pullup = <0 1 0 1>;
                     pinctrl-single,drive-strength = <0x10 0x70>;
                     pinctrl-single,slew-rate = <0x0 0x80>;
		};
		gpio049_cfg_idle: gpio049_cfg_idle {
                     pinctrl-single,pins = <0x20  0>;
                     pinctrl-single,bias-pulldown = <0 2 0 2>;
                     pinctrl-single,bias-pullup = <0 1 0 1>;
                     pinctrl-single,drive-strength = <0x10 0x70>;
                     pinctrl-single,slew-rate = <0x0 0x80>;
		};

		gpio050_cfg_func: gpio050_cfg_func {
                     pinctrl-single,pins = <0x24  0>;
                     pinctrl-single,bias-pulldown = <0 2 0 2>;
                     pinctrl-single,bias-pullup = <0 1 0 1>;
                     pinctrl-single,drive-strength = <0x10 0x70>;
                     pinctrl-single,slew-rate = <0x0 0x80>;
		};
		gpio050_cfg_idle: gpio050_cfg_idle {
                     pinctrl-single,pins = <0x24  0>;
                     pinctrl-single,bias-pulldown = <0 2 0 2>;
                     pinctrl-single,bias-pullup = <0 1 0 1>;
                     pinctrl-single,drive-strength = <0x10 0x70>;
                     pinctrl-single,slew-rate = <0x0 0x80>;
		};

		gpio051_cfg_func: gpio051_cfg_func {
                     pinctrl-single,pins = <0x28  0>;
                     pinctrl-single,bias-pulldown = <0 2 0 2>;
                     pinctrl-single,bias-pullup = <0 1 0 1>;
                     pinctrl-single,drive-strength = <0x20 0x70>;
		};
		gpio051_cfg_idle: gpio051_cfg_idle {
                     pinctrl-single,pins = <0x28  0>;
                     pinctrl-single,bias-pulldown = <0 2 0 2>;
                     pinctrl-single,bias-pullup = <0 1 0 1>;
                     pinctrl-single,drive-strength = <0x20 0x70>;
		};

		gpio052_cfg_func: gpio052_cfg_func {
                     pinctrl-single,pins = <0x2C  0>;
                     pinctrl-single,bias-pulldown = <0 2 0 2>;
                     pinctrl-single,bias-pullup = <0 1 0 1>;
                     pinctrl-single,drive-strength = <0x20 0x70>;
                     pinctrl-single,slew-rate = <0x0 0x80>;
		};
		gpio052_cfg_idle: gpio052_cfg_idle {
                     pinctrl-single,pins = <0x2C  0>;
                     pinctrl-single,bias-pulldown = <0 2 0 2>;
                     pinctrl-single,bias-pullup = <0 1 0 1>;
                     pinctrl-single,drive-strength = <0x20 0x70>;
                     pinctrl-single,slew-rate = <0x0 0x80>;
		};

		gpio053_cfg_func: gpio053_cfg_func {
                     pinctrl-single,pins = <0x30  0>;
                     pinctrl-single,bias-pulldown = <0 2 0 2>;
                     pinctrl-single,bias-pullup = <0 1 0 1>;
                     pinctrl-single,drive-strength = <0x20 0x70>;
                     pinctrl-single,slew-rate = <0x0 0x80>;
		};
		gpio053_cfg_idle: gpio053_cfg_idle {
                     pinctrl-single,pins = <0x30  0>;
                     pinctrl-single,bias-pulldown = <0 2 0 2>;
                     pinctrl-single,bias-pullup = <0 1 0 1>;
                     pinctrl-single,drive-strength = <0x20 0x70>;
                     pinctrl-single,slew-rate = <0x0 0x80>;
		};

		gpio054_cfg_func: gpio054_cfg_func {
                     pinctrl-single,pins = <0x34  0>;
                     pinctrl-single,bias-pulldown = <0 2 0 2>;
                     pinctrl-single,bias-pullup = <0 1 0 1>;
                     pinctrl-single,drive-strength = <0x20 0x70>;
                     pinctrl-single,slew-rate = <0x0 0x80>;
		};
		gpio054_cfg_idle: gpio054_cfg_idle {
                     pinctrl-single,pins = <0x34  0>;
                     pinctrl-single,bias-pulldown = <0 2 0 2>;
                     pinctrl-single,bias-pullup = <0 1 0 1>;
                     pinctrl-single,drive-strength = <0x20 0x70>;
                     pinctrl-single,slew-rate = <0x0 0x80>;
		};

		gpio056_cfg_func: gpio056_cfg_func {
                     pinctrl-single,pins = <0x38  0>;
                     pinctrl-single,bias-pulldown = <0 2 0 2>;
                     pinctrl-single,bias-pullup = <0 1 0 1>;
                     pinctrl-single,drive-strength = <0x20 0x70>;
                     pinctrl-single,slew-rate = <0x0 0x80>;
		};
		gpio056_cfg_idle: gpio056_cfg_idle {
                     pinctrl-single,pins = <0x38  0>;
                     pinctrl-single,bias-pulldown = <0 2 0 2>;
                     pinctrl-single,bias-pullup = <0 1 0 1>;
                     pinctrl-single,drive-strength = <0x20 0x70>;
                     pinctrl-single,slew-rate = <0x0 0x80>;
		};

		gpio057_cfg_func: gpio057_cfg_func {
                     pinctrl-single,pins = <0x3C  0>;
                     pinctrl-single,bias-pulldown = <0 2 0 2>;
                     pinctrl-single,bias-pullup = <0 1 0 1>;
                     pinctrl-single,drive-strength = <0x20 0x70>;
                     pinctrl-single,slew-rate = <0x0 0x80>;
		};
		gpio057_cfg_idle: gpio057_cfg_idle {
                     pinctrl-single,pins = <0x3C  0>;
                     pinctrl-single,bias-pulldown = <0 2 0 2>;
                     pinctrl-single,bias-pullup = <0 1 0 1>;
                     pinctrl-single,drive-strength = <0x20 0x70>;
                     pinctrl-single,slew-rate = <0x0 0x80>;
		};

		gpio058_cfg_func: gpio058_cfg_func {
                     pinctrl-single,pins = <0x40  0>;
                     pinctrl-single,bias-pulldown = <0 2 0 2>;
                     pinctrl-single,bias-pullup = <0 1 0 1>;
                     pinctrl-single,drive-strength = <0x20 0x70>;
                     pinctrl-single,slew-rate = <0x0 0x80>;
		};
		gpio058_cfg_idle: gpio058_cfg_idle {
                     pinctrl-single,pins = <0x40  0>;
                     pinctrl-single,bias-pulldown = <0 2 0 2>;
                     pinctrl-single,bias-pullup = <0 1 0 1>;
                     pinctrl-single,drive-strength = <0x20 0x70>;
                     pinctrl-single,slew-rate = <0x0 0x80>;
		};

		gpio059_cfg_func: gpio059_cfg_func {
                     pinctrl-single,pins = <0x44  0>;
                     pinctrl-single,bias-pulldown = <0 2 0 2>;
                     pinctrl-single,bias-pullup = <0 1 0 1>;
                     pinctrl-single,drive-strength = <0x20 0x70>;
                     pinctrl-single,slew-rate = <0x0 0x80>;
		};
		gpio059_cfg_idle: gpio059_cfg_idle {
                     pinctrl-single,pins = <0x44  0>;
                     pinctrl-single,bias-pulldown = <0 2 0 2>;
                     pinctrl-single,bias-pullup = <0 1 0 1>;
                     pinctrl-single,drive-strength = <0x20 0x70>;
                     pinctrl-single,slew-rate = <0x0 0x80>;
		};

		gpio062_cfg_func: gpio062_cfg_func {
                     pinctrl-single,pins = <0x48  0>;
                     pinctrl-single,bias-pulldown = <0 2 0 2>;
                     pinctrl-single,bias-pullup = <0 1 0 1>;
                     pinctrl-single,drive-strength = <0x20 0x70>;
                     pinctrl-single,slew-rate = <0x0 0x80>;
		};
		gpio062_cfg_idle: gpio062_cfg_idle {
                     pinctrl-single,pins = <0x48  0>;
                     pinctrl-single,bias-pulldown = <0 2 0 2>;
                     pinctrl-single,bias-pullup = <0 1 0 1>;
                     pinctrl-single,drive-strength = <0x20 0x70>;
                     pinctrl-single,slew-rate = <0x0 0x80>;
		};

		gpio063_cfg_func: gpio063_cfg_func {
                     pinctrl-single,pins = <0x4C  0>;
                     pinctrl-single,bias-pulldown = <0 2 0 2>;
                     pinctrl-single,bias-pullup = <0 1 0 1>;
                     pinctrl-single,drive-strength = <0x20 0x70>;
                     pinctrl-single,slew-rate = <0x0 0x80>;
		};
		gpio063_cfg_idle: gpio063_cfg_idle {
                     pinctrl-single,pins = <0x4C  0>;
                     pinctrl-single,bias-pulldown = <0 2 0 2>;
                     pinctrl-single,bias-pullup = <0 1 0 1>;
                     pinctrl-single,drive-strength = <0x20 0x70>;
                     pinctrl-single,slew-rate = <0x0 0x80>;
		};

		gpio064_cfg_func: gpio064_cfg_func {
                     pinctrl-single,pins = <0x50  0>;
                     pinctrl-single,bias-pulldown = <0 2 0 2>;
                     pinctrl-single,bias-pullup = <0 1 0 1>;
                     pinctrl-single,drive-strength = <0x20 0x70>;
                     pinctrl-single,slew-rate = <0x0 0x80>;
		};
		gpio064_cfg_idle: gpio064_cfg_idle {
                     pinctrl-single,pins = <0x50  0>;
                     pinctrl-single,bias-pulldown = <0 2 0 2>;
                     pinctrl-single,bias-pullup = <0 1 0 1>;
                     pinctrl-single,drive-strength = <0x20 0x70>;
                     pinctrl-single,slew-rate = <0x0 0x80>;
		};

		gpio065_cfg_func: gpio065_cfg_func {
                     pinctrl-single,pins = <0x54  0>;
                     pinctrl-single,bias-pulldown = <0 2 0 2>;
                     pinctrl-single,bias-pullup = <0 1 0 1>;
                     pinctrl-single,drive-strength = <0x20 0x70>;
                     pinctrl-single,slew-rate = <0x0 0x80>;
		};
		gpio065_cfg_idle: gpio065_cfg_idle {
                     pinctrl-single,pins = <0x54  0>;
                     pinctrl-single,bias-pulldown = <0 2 0 2>;
                     pinctrl-single,bias-pullup = <0 1 0 1>;
                     pinctrl-single,drive-strength = <0x20 0x70>;
                     pinctrl-single,slew-rate = <0x0 0x80>;
		};

		gpio066_cfg_func: gpio066_cfg_func {
                     pinctrl-single,pins = <0x58  0>;
                     pinctrl-single,bias-pulldown = <0 2 0 2>;
                     pinctrl-single,bias-pullup = <0 1 0 1>;
                     pinctrl-single,drive-strength = <0x20 0x70>;
                     pinctrl-single,slew-rate = <0x0 0x80>;
		};
		gpio066_cfg_idle: gpio066_cfg_idle {
                     pinctrl-single,pins = <0x58  0>;
                     pinctrl-single,bias-pulldown = <0 2 0 2>;
                     pinctrl-single,bias-pullup = <0 1 0 1>;
                     pinctrl-single,drive-strength = <0x20 0x70>;
                     pinctrl-single,slew-rate = <0x0 0x80>;
		};

		gpio067_cfg_func: gpio067_cfg_func {
                     pinctrl-single,pins = <0x5C  0>;
                     pinctrl-single,bias-pulldown = <0 2 0 2>;
                     pinctrl-single,bias-pullup = <0 1 0 1>;
                     pinctrl-single,drive-strength = <0x20 0x70>;
                     pinctrl-single,slew-rate = <0x0 0x80>;
		};
		gpio067_cfg_idle: gpio067_cfg_idle {
                     pinctrl-single,pins = <0x5C  0>;
                     pinctrl-single,bias-pulldown = <0 2 0 2>;
                     pinctrl-single,bias-pullup = <0 1 0 1>;
                     pinctrl-single,drive-strength = <0x20 0x70>;
                     pinctrl-single,slew-rate = <0x0 0x80>;
		};

		gpio068_cfg_func: gpio068_cfg_func {
                     pinctrl-single,pins = <0x60  0>;
                     pinctrl-single,bias-pulldown = <0 2 0 2>;
                     pinctrl-single,bias-pullup = <0 1 0 1>;
                     pinctrl-single,drive-strength = <0x20 0x70>;
                     pinctrl-single,slew-rate = <0x0 0x80>;
		};
		gpio068_cfg_idle: gpio068_cfg_idle {
                     pinctrl-single,pins = <0x60  0>;
                     pinctrl-single,bias-pulldown = <0 2 0 2>;
                     pinctrl-single,bias-pullup = <0 1 0 1>;
                     pinctrl-single,drive-strength = <0x20 0x70>;
                     pinctrl-single,slew-rate = <0x0 0x80>;
		};

		gpio071_cfg_func: gpio071_cfg_func {
                     pinctrl-single,pins = <0x64  0>;
                     pinctrl-single,bias-pulldown = <0 2 0 2>;
                     pinctrl-single,bias-pullup = <0 1 0 1>;
                     pinctrl-single,drive-strength = <0x20 0x70>;
                     pinctrl-single,slew-rate = <0x0 0x80>;
		};
		gpio071_cfg_idle: gpio071_cfg_idle {
                     pinctrl-single,pins = <0x64  0>;
                     pinctrl-single,bias-pulldown = <0 2 0 2>;
                     pinctrl-single,bias-pullup = <0 1 0 1>;
                     pinctrl-single,drive-strength = <0x20 0x70>;
                     pinctrl-single,slew-rate = <0x0 0x80>;
		};

		gpio072_cfg_func: gpio072_cfg_func {
                     pinctrl-single,pins = <0x68  0>;
                     pinctrl-single,bias-pulldown = <0 2 0 2>;
                     pinctrl-single,bias-pullup = <0 1 0 1>;
                     pinctrl-single,drive-strength = <0x20 0x70>;
                     pinctrl-single,slew-rate = <0x0 0x80>;
		};
		gpio072_cfg_idle: gpio072_cfg_idle {
                     pinctrl-single,pins = <0x68  0>;
                     pinctrl-single,bias-pulldown = <0 2 0 2>;
                     pinctrl-single,bias-pullup = <0 1 0 1>;
                     pinctrl-single,drive-strength = <0x20 0x70>;
                     pinctrl-single,slew-rate = <0x0 0x80>;
		};

		gpio074_cfg_func: gpio074_cfg_func {
                     pinctrl-single,pins = <0x6C  0>;
                     pinctrl-single,bias-pulldown = <0 2 0 2>;
                     pinctrl-single,bias-pullup = <0 1 0 1>;
                     pinctrl-single,drive-strength = <0x20 0x70>;
                     pinctrl-single,slew-rate = <0x0 0x80>;
		};
		gpio074_cfg_idle: gpio074_cfg_idle {
                     pinctrl-single,pins = <0x6C  0>;
                     pinctrl-single,bias-pulldown = <0 2 0 2>;
                     pinctrl-single,bias-pullup = <0 1 0 1>;
                     pinctrl-single,drive-strength = <0x20 0x70>;
                     pinctrl-single,slew-rate = <0x0 0x80>;
		};

		gpio075_cfg_func: gpio075_cfg_func {
                     pinctrl-single,pins = <0x70  0>;
                     pinctrl-single,bias-pulldown = <0 2 0 2>;
                     pinctrl-single,bias-pullup = <0 1 0 1>;
                     pinctrl-single,drive-strength = <0x20 0x70>;
                     pinctrl-single,slew-rate = <0x0 0x80>;
		};
		gpio075_cfg_idle: gpio075_cfg_idle {
                     pinctrl-single,pins = <0x70  0>;
                     pinctrl-single,bias-pulldown = <0 2 0 2>;
                     pinctrl-single,bias-pullup = <0 1 0 1>;
                     pinctrl-single,drive-strength = <0x20 0x70>;
                     pinctrl-single,slew-rate = <0x0 0x80>;
		};

		gpio077_cfg_func: gpio077_cfg_func {
                     pinctrl-single,pins = <0x74  0>;
                     pinctrl-single,bias-pulldown = <0 2 0 2>;
                     pinctrl-single,bias-pullup = <0 1 0 1>;
                     pinctrl-single,drive-strength = <0x20 0x70>;
                     pinctrl-single,slew-rate = <0x0 0x80>;
		};
		gpio077_cfg_idle: gpio077_cfg_idle {
                     pinctrl-single,pins = <0x74  0>;
                     pinctrl-single,bias-pulldown = <0 2 0 2>;
                     pinctrl-single,bias-pullup = <0 1 0 1>;
                     pinctrl-single,drive-strength = <0x20 0x70>;
                     pinctrl-single,slew-rate = <0x0 0x80>;
		};

		gpio078_cfg_func: gpio078_cfg_func {
                     pinctrl-single,pins = <0x78  0>;
                     pinctrl-single,bias-pulldown = <0 2 0 2>;
                     pinctrl-single,bias-pullup = <0 1 0 1>;
                     pinctrl-single,drive-strength = <0x20 0x70>;
                     pinctrl-single,slew-rate = <0x0 0x80>;
		};
		gpio078_cfg_idle: gpio078_cfg_idle {
                     pinctrl-single,pins = <0x78  0>;
                     pinctrl-single,bias-pulldown = <0 2 0 2>;
                     pinctrl-single,bias-pullup = <0 1 0 1>;
                     pinctrl-single,drive-strength = <0x20 0x70>;
                     pinctrl-single,slew-rate = <0x0 0x80>;
		};

		gpio079_cfg_func: gpio079_cfg_func {
                     pinctrl-single,pins = <0x7C  0>;
                     pinctrl-single,bias-pulldown = <0 2 0 2>;
                     pinctrl-single,bias-pullup = <0 1 0 1>;
                     pinctrl-single,drive-strength = <0x20 0x70>;
                     pinctrl-single,slew-rate = <0x0 0x80>;
		};
		gpio079_cfg_idle: gpio079_cfg_idle {
                     pinctrl-single,pins = <0x7C  0>;
                     pinctrl-single,bias-pulldown = <0 2 0 2>;
                     pinctrl-single,bias-pullup = <0 1 0 1>;
                     pinctrl-single,drive-strength = <0x20 0x70>;
                     pinctrl-single,slew-rate = <0x0 0x80>;
		};

		gpio080_cfg_func: gpio080_cfg_func {
                     pinctrl-single,pins = <0x80  0>;
                     pinctrl-single,bias-pulldown = <0 2 0 2>;
                     pinctrl-single,bias-pullup = <0 1 0 1>;
                     pinctrl-single,drive-strength = <0x20 0x70>;
                     pinctrl-single,slew-rate = <0x0 0x80>;
		};
		gpio080_cfg_idle: gpio080_cfg_idle {
                     pinctrl-single,pins = <0x80  0>;
                     pinctrl-single,bias-pulldown = <0 2 0 2>;
                     pinctrl-single,bias-pullup = <0 1 0 1>;
                     pinctrl-single,drive-strength = <0x20 0x70>;
                     pinctrl-single,slew-rate = <0x0 0x80>;
		};

		gpio081_cfg_func: gpio081_cfg_func {
                     pinctrl-single,pins = <0x84  0>;
                     pinctrl-single,bias-pulldown = <0 2 0 2>;
                     pinctrl-single,bias-pullup = <0 1 0 1>;
                     pinctrl-single,drive-strength = <0x20 0x70>;
                     pinctrl-single,slew-rate = <0x0 0x80>;
		};
		gpio081_cfg_idle: gpio081_cfg_idle {
                     pinctrl-single,pins = <0x84  0>;
                     pinctrl-single,bias-pulldown = <0 2 0 2>;
                     pinctrl-single,bias-pullup = <0 1 0 1>;
                     pinctrl-single,drive-strength = <0x20 0x70>;
                     pinctrl-single,slew-rate = <0x0 0x80>;
		};

		gpio082_cfg_func: gpio082_cfg_func {
                     pinctrl-single,pins = <0x88  0>;
                     pinctrl-single,bias-pulldown = <0 2 0 2>;
                     pinctrl-single,bias-pullup = <0 1 0 1>;
                     pinctrl-single,drive-strength = <0x20 0x70>;
                     pinctrl-single,slew-rate = <0x0 0x80>;
		};
		gpio082_cfg_idle: gpio082_cfg_idle {
                     pinctrl-single,pins = <0x88  0>;
                     pinctrl-single,bias-pulldown = <0 2 0 2>;
                     pinctrl-single,bias-pullup = <0 1 0 1>;
                     pinctrl-single,drive-strength = <0x20 0x70>;
                     pinctrl-single,slew-rate = <0x0 0x80>;
		};

		gpio084_cfg_func: gpio084_cfg_func {
                     pinctrl-single,pins = <0x8C  0>;
                     pinctrl-single,bias-pulldown = <0 2 0 2>;
                     pinctrl-single,bias-pullup = <0 1 0 1>;
                     pinctrl-single,drive-strength = <0x20 0x70>;
                     pinctrl-single,slew-rate = <0x0 0x80>;
		};
		gpio084_cfg_idle: gpio084_cfg_idle {
                     pinctrl-single,pins = <0x8C  0>;
                     pinctrl-single,bias-pulldown = <0 2 0 2>;
                     pinctrl-single,bias-pullup = <0 1 0 1>;
                     pinctrl-single,drive-strength = <0x20 0x70>;
                     pinctrl-single,slew-rate = <0x0 0x80>;
		};

		gpio085_cfg_func: gpio085_cfg_func {
                     pinctrl-single,pins = <0x90  0>;
                     pinctrl-single,bias-pulldown = <0 2 0 2>;
                     pinctrl-single,bias-pullup = <0 1 0 1>;
                     pinctrl-single,drive-strength = <0x20 0x70>;
                     pinctrl-single,slew-rate = <0x0 0x80>;
		};
		gpio085_cfg_idle: gpio085_cfg_idle {
                     pinctrl-single,pins = <0x90  0>;
                     pinctrl-single,bias-pulldown = <0 2 0 2>;
                     pinctrl-single,bias-pullup = <0 1 0 1>;
                     pinctrl-single,drive-strength = <0x20 0x70>;
                     pinctrl-single,slew-rate = <0x0 0x80>;
		};

		gpio086_cfg_func: gpio086_cfg_func {
                     pinctrl-single,pins = <0x94  0>;
                     pinctrl-single,bias-pulldown = <0 2 0 2>;
                     pinctrl-single,bias-pullup = <0 1 0 1>;
                     pinctrl-single,drive-strength = <0x20 0x70>;
                     pinctrl-single,slew-rate = <0x0 0x80>;
		};
		gpio086_cfg_idle: gpio086_cfg_idle {
                     pinctrl-single,pins = <0x94  0>;
                     pinctrl-single,bias-pulldown = <0 2 0 2>;
                     pinctrl-single,bias-pullup = <0 1 0 1>;
                     pinctrl-single,drive-strength = <0x20 0x70>;
                     pinctrl-single,slew-rate = <0x0 0x80>;
		};

		gpio087_cfg_func: gpio087_cfg_func {
                     pinctrl-single,pins = <0x98  0>;
                     pinctrl-single,bias-pulldown = <0 2 0 2>;
                     pinctrl-single,bias-pullup = <0 1 0 1>;
                     pinctrl-single,drive-strength = <0x20 0x70>;
                     pinctrl-single,slew-rate = <0x0 0x80>;
		};
		gpio087_cfg_idle: gpio087_cfg_idle {
                     pinctrl-single,pins = <0x98  0>;
                     pinctrl-single,bias-pulldown = <0 2 0 2>;
                     pinctrl-single,bias-pullup = <0 1 0 1>;
                     pinctrl-single,drive-strength = <0x20 0x70>;
                     pinctrl-single,slew-rate = <0x0 0x80>;
		};

		gpio088_cfg_func: gpio088_cfg_func {
                     pinctrl-single,pins = <0x9C  0>;
                     pinctrl-single,bias-pulldown = <0 2 0 2>;
                     pinctrl-single,bias-pullup = <0 1 0 1>;
                     pinctrl-single,drive-strength = <0x20 0x70>;
                     pinctrl-single,slew-rate = <0x0 0x80>;
		};
		gpio088_cfg_idle: gpio088_cfg_idle {
                     pinctrl-single,pins = <0x9C  0>;
                     pinctrl-single,bias-pulldown = <0 2 0 2>;
                     pinctrl-single,bias-pullup = <0 1 0 1>;
                     pinctrl-single,drive-strength = <0x20 0x70>;
                     pinctrl-single,slew-rate = <0x0 0x80>;
		};

		gpio089_cfg_func: gpio089_cfg_func {
                     pinctrl-single,pins = <0xA0  0>;
                     pinctrl-single,bias-pulldown = <0 2 0 2>;
                     pinctrl-single,bias-pullup = <0 1 0 1>;
                     pinctrl-single,drive-strength = <0x20 0x70>;
                     pinctrl-single,slew-rate = <0x0 0x80>;
		};
		gpio089_cfg_idle: gpio089_cfg_idle {
                     pinctrl-single,pins = <0xA0  0>;
                     pinctrl-single,bias-pulldown = <0 2 0 2>;
                     pinctrl-single,bias-pullup = <0 1 0 1>;
                     pinctrl-single,drive-strength = <0x20 0x70>;
                     pinctrl-single,slew-rate = <0x0 0x80>;
		};

		gpio090_cfg_func: gpio090_cfg_func {
                     pinctrl-single,pins = <0xA4  0>;
                     pinctrl-single,bias-pulldown = <0 2 0 2>;
                     pinctrl-single,bias-pullup = <0 1 0 1>;
                     pinctrl-single,drive-strength = <0x40 0x70>;
                     pinctrl-single,slew-rate = <0x0 0x80>;
		};
		gpio090_cfg_idle: gpio090_cfg_idle {
                     pinctrl-single,pins = <0xA4  0>;
                     pinctrl-single,bias-pulldown = <0 2 0 2>;
                     pinctrl-single,bias-pullup = <0 1 0 1>;
                     pinctrl-single,drive-strength = <0x40 0x70>;
                     pinctrl-single,slew-rate = <0x0 0x80>;
		};

    };

};
